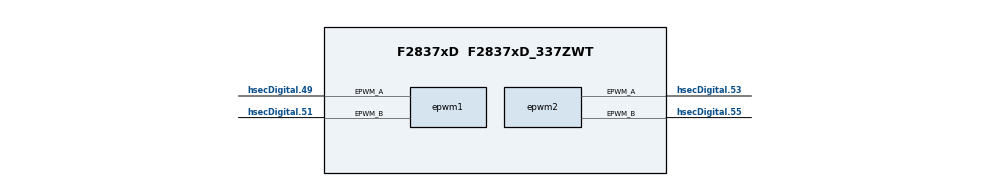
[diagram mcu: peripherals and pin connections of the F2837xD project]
/**
 * @cliArgs --board "/boards/TMDSCNCD28379D" --device "F2837xD" --part "F2837xD_337ZWT" --package "F2837xD_337ZWT" --context "CPU1" --product "C2000WARE@6.00.01.00"
 * @versions {"tool":"1.26.0+4407"}
 */

/**
 * Import the modules used in this configuration.
 */
const adc              = scripting.addModule("/driverlib/adc.js", {}, false);
const adc1             = adc.addInstance();
const led              = scripting.addModule("/driverlib/board_components/led", {}, false);
const led1             = led.addInstance();
const device_support   = scripting.addModule("/driverlib/device_support.js");
const ecap             = scripting.addModule("/driverlib/ecap.js", {}, false);
const ecap1            = ecap.addInstance();
const epwm             = scripting.addModule("/driverlib/epwm.js", {}, false);
const epwm1            = epwm.addInstance();
const epwm2            = epwm.addInstance();
const inputxbar        = scripting.addModule("/driverlib/inputxbar.js", {}, false);
const inputxbar1       = inputxbar.addInstance();
const inputxbar_input  = scripting.addModule("/driverlib/inputxbar_input.js");
const inputxbar_input1 = inputxbar_input.addInstance();

/**
 * Write custom configuration values to the imported modules.
 */
adc1.$name                          = "myADC0";
adc1.adcClockPrescaler              = "ADC_CLK_DIV_4_0";
adc1.enabledSOCs                    = ["ADC_SOC_NUMBER0"];
adc1.enabledInts                    = ["ADC_INT_NUMBER1"];
adc1.enableInterrupt1               = true;
adc1.enableInterrupt1ContinuousMode = true;
adc1.registerInterrupts             = ["1"];
adc1.soc0Trigger                    = "ADC_TRIGGER_EPWM2_SOCA";
adc1.interruptPulseMode             = "ADC_PULSE_END_OF_CONV";
adc1.soc0SampleWindow               = 15;
adc1.adcInt1.interruptHandler       = "adcA1ISR";
adc1.adcInt1.enableInterrupt        = true;

led1.$name     = "myBoardLED0";
led1.$hardware = system.deviceData.board.components.D2;

const divider3 = system.clockTree["EPWMCLKDIV"];
scripting.suppress("ePWM TZFRC and TZCLR events will sometimes be missed when EPWMCLKDIV is divide by 2\\. Always program EPWMCLKDIV to divide by 1 if using TZFRC or TZCLR register\\. Please refer to the F2837xD Silicon Errata for more details\\.", divider3, "EPWMCLK");

const multiplier4         = system.clockTree["PLL_IMULT"];
multiplier4.multiplyValue = 20;

const pinFunction3     = system.clockTree["XTAL"];
pinFunction3.XTAL_Freq = 20;

ecap1.$name                    = "myECAP0";
ecap1.eventStop                = "ECAP_EVENT_4";
ecap1.eventTwoPolarity         = "ECAP_EVNT_FALLING_EDGE";
ecap1.eventFourPolarity        = "ECAP_EVNT_FALLING_EDGE";
ecap1.registerInterrupts       = true;
ecap1.enableInterrupt          = true;
ecap1.interruptSourceCapture   = ["ECAP_ISR_SOURCE_CAPTURE_EVENT_3"];
ecap1.ecapInt.interruptHandler = "ecap1ISR";
ecap1.ecapInt.enableInterrupt  = true;

epwm1.$name                                                      = "myEPWM0";
epwm1.epwmTimebase_counterMode                                   = "EPWM_COUNTER_MODE_UP_DOWN";
epwm1.epwmTimebase_period                                        = 25000;
epwm1.epwmActionQualifier_EPWM_AQ_OUTPUT_A_shadowMode            = true;
epwm1.epwmActionQualifier_EPWM_AQ_OUTPUT_A_ON_TIMEBASE_UP_CMPA   = "EPWM_AQ_OUTPUT_HIGH";
epwm1.epwmActionQualifier_EPWM_AQ_OUTPUT_A_ON_TIMEBASE_DOWN_CMPA = "EPWM_AQ_OUTPUT_LOW";
epwm1.epwmTripZone_useAdvancedEPWMTripZoneActions                = true;
epwm1.epwm.$assign                                               = "EPWM1";
epwm1.epwm.epwm_aPin.$assign                                     = "hsecDigital.49";
epwm1.epwm.epwm_bPin.$assign                                     = "hsecDigital.51";
scripting.suppress("It is recommended to use a non-zero counter compare value when using shadow to active load of action qualifier A/B control register on TBCTR=0 boundary", epwm1, "epwmCounterCompare_cmpA");
scripting.suppress("It is recommended to use a non-zero counter compare value when using shadow to active load of action qualifier A/B control register on TBCTR=0 boundary", epwm1, "epwmCounterCompare_cmpB");
scripting.suppress("Connected to hardware,@@@.+?@@@ is connected to EPWM1 on the Control Card F28379D\\. Consider selecting it in \'use hardware\' above\\. @@@.+?@@@", epwm1.epwm, "epwm_aPin");
scripting.suppress("Connected to hardware,@@@.+?@@@ is connected to EPWM1 on the Control Card F28379D\\. Consider selecting it in \'use hardware\' above\\. @@@.+?@@@", epwm1.epwm, "epwm_bPin");

epwm2.$name                                             = "myEPWM2";
epwm2.epwmTimebase_period                               = 1999;
epwm2.epwmTimebase_counterMode                          = "EPWM_COUNTER_MODE_UP";
epwm2.epwmEventTrigger_EPWM_SOC_A_triggerEnable         = true;
epwm2.epwmEventTrigger_EPWM_SOC_A_triggerSource         = "EPWM_SOC_TBCTR_PERIOD";
epwm2.epwmEventTrigger_EPWM_SOC_A_triggerEventPrescalar = "1";
epwm2.epwm.$assign                                      = "EPWM2";
epwm2.epwm.epwm_aPin.$assign                            = "hsecDigital.53";
epwm2.epwm.epwm_bPin.$assign                            = "hsecDigital.55";
scripting.suppress("Connected to hardware,@@@.+?@@@ is connected to EPWM2 on the Control Card F28379D\\. Consider selecting it in \'use hardware\' above\\. @@@.+?@@@", epwm2.epwm, "epwm_aPin");
scripting.suppress("Connected to hardware,@@@.+?@@@ is connected to EPWM2 on the Control Card F28379D\\. Consider selecting it in \'use hardware\' above\\. @@@.+?@@@", epwm2.epwm, "epwm_bPin");

inputxbar1.$name = "myINPUTXBAR0";

inputxbar_input1.$name          = "myINPUTXBARINPUT0";
inputxbar_input1.inputxbarInput = "XBAR_INPUT7";

/**
 * Pinmux solution for unlocked pins/peripherals. This ensures that minor changes to the automatic solver in a future
 * version of the tool will not impact the pinmux you originally saw.  These lines can be completely deleted in order to
 * re-solve from scratch.
 */
led1.gpio.gpioPin.$suggestSolution = "hsecDigital.86";
